# AM335x register map
Vendor: Texas Instruments; Series: Sitara AM335x; File version: 1.1
CPU: Cortex-A8 r0p0, little endian
Registers are 32-bit, read-write, reset 0x0 unless marked. A register's access mark holds for its fields unless they carry their own. Offsets are from the block's base; [hi:lo] are bit positions; 'fields as' and 'values as' point back to an identical list.

## CM_MPU — Clock Module - MPU
Base 0x44E00600
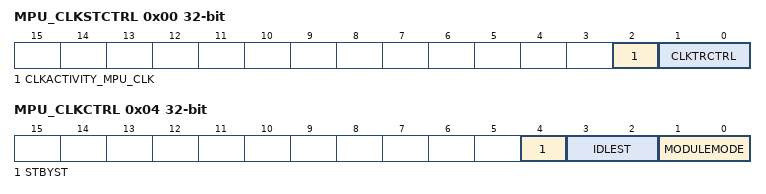
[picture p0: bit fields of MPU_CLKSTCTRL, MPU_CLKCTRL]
0x00 MPU_CLKSTCTRL
  [2] CLKACTIVITY_MPU_CLK — bit: 2 (R)This field indicates the state of the MPU Clock [see e_PRCM_CLK_DOMAIN_ST]
  [1:0] CLKTRCTRL — bit: 0,1 (RW)Clock state transition [see e_PRCM_CLKTRCTRL]
0x04 MPU_CLKCTRL — CM_STBY_CLKCTRL Register
  [4] STBYST — bit: 18 (R)Module standby status.[see e_PRCM_STBYST]
  [3:2] IDLEST — bit: 16,17 (R)Module idle status.[see e_PRCM_IDLEST]
  [1:0] MODULEMODE — bit: 0,1 (RW)Control the way mandatory clocks are managed.[see e_PRCM_MODULEMODE]

## CM_RTC — Clock Module - RTC
Base 0x44E00800
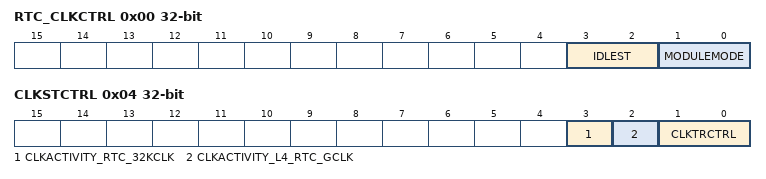
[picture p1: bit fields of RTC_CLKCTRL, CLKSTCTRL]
0x00 RTC_CLKCTRL — CM_CLKCTRL Register
  [3:2] IDLEST — bit: 16,17 (R)Module idle status.[see e_PRCM_IDLEST]
  [1:0] MODULEMODE — bit: 0,1 (RW)Control the way mandatory clocks are managed.[see e_PRCM_MODULEMODE]
0x04 CLKSTCTRL — RTC_CLKSTCTRL Register
  [3] CLKACTIVITY_RTC_32KCLK — bit: 9 (R)This field indicates the state of the 32K RTC clock in the domain [0x0 = Inact; 0x1 = Act]
  [2] CLKACTIVITY_L4_RTC_GCLK — bit: 8 (R)This field indicates the state of the L4 RTC clock in the domain. [0x0 = Inact; 0x1 = Act]
  [1:0] CLKTRCTRL — bit: 0,1 (RW)Clock state transition [see e_PRCM_CLKTRCTRL]

## PRM_CEFUSE — Power Reset Module - CEFUSE
Base 0x44E01200
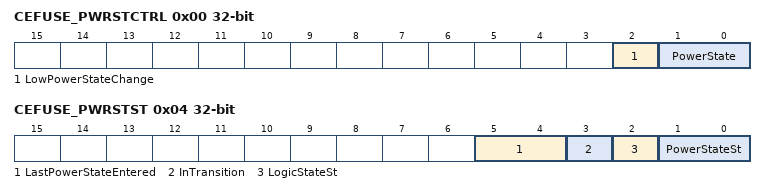
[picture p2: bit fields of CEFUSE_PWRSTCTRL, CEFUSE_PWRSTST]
0x00 CEFUSE_PWRSTCTRL
  [2] LowPowerStateChange — bit: 4 (RW) Power state change request when domain has already performed a sleep transition [0x0 = Do not request; 0x1 = Request a low power state change]
  [1:0] PowerState — bit: 0,1 (RW) Power state control [see e_CEFUSE_PWRSTATE_CTRL]
0x04 CEFUSE_PWRSTST
  [5:4] LastPowerStateEntered — bit: 24,25 (RW)Last low power state entered.Set to 0x3 upon write of the same only. [0x0 = OFF; 0x1 = ON]
  [3] InTransition — bit: 20 (R)Domain transition status [0x0 = No on-going transition; 0x1 = transition is in progress.]
  [2] LogicStateSt — bit: 2 (R)Logic state status [0x0 = logic in domain OFF; 0x1 = logic in domain ON]
  [1:0] PowerStateSt — bit: 0,1 (R)Current Power State Status [see e_CEFUSE_PWRSTST]

## PRM_GFX — Power Reset Module - GFX
Base 0x44E01100
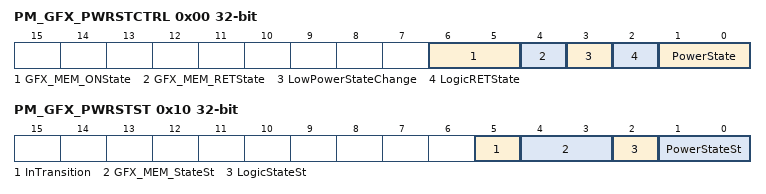
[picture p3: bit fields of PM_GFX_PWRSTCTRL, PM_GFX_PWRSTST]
0x00 PM_GFX_PWRSTCTRL
  [6:5] GFX_MEM_ONState — bit: 17,18 (R) GFX memory state when domain is ON.
  [4] GFX_MEM_RETState — bit: 6 (RW)
  [3] LowPowerStateChange — bit: 4 (RW) Power state change request when domain has already performed a sleep transition [0x0 = Do not request; 0x1 = Request a low power state change]
  [2] LogicRETState — bit: 2 (RW) Logic state when power domain is RETENTION [0x0 = logic_off; 0x1 = logic_ret]
  [1:0] PowerState — bit: 0,1 (RW) Power state control [see e_PWR_STATE_CTRL]
0x04 RM_GFX_RSTCTRL
  [0] GFX_RST — bit: 0 (RW) GFX domain local reset control for (SGX 530) [0x0 = CLEAR; 0x1 = ASSERT]
0x10 PM_GFX_PWRSTST
  [5] InTransition — bit: 20 (R)Domain transition status [0x0 = No on-going transition on power domain; 0x1 = Power domain transition is in progress]
  [4:3] GFX_MEM_StateSt — bit: 4,5 (R)GFX memory state status [see e_GFX_MEMSTST]
  [2] LogicStateSt — bit: 2 (R)Logic state status [0x0 = logic in domain OFF; 0x1 = logic in domain ON]
  [1:0] PowerStateSt — bit: 0,1 (R)Current Power State Status [see e_GFX_PWRSTST]
0x14 RM_GFX_RSTST
  [0] GFX_RST — bit: 0 (RW) GFX Domain Logic Reset [0x0 = RESET_NO; 0x1 = RESET_YES]

## PRM_IRQ — Power Reset Module - IRQ
Base 0x44E00B00
0x00 REVISION
  [7:0] REV — IP revision [7:4] Major revision [3:0] Minor revision Examples: 0x10 for 1.0, 0x21 for 2.1
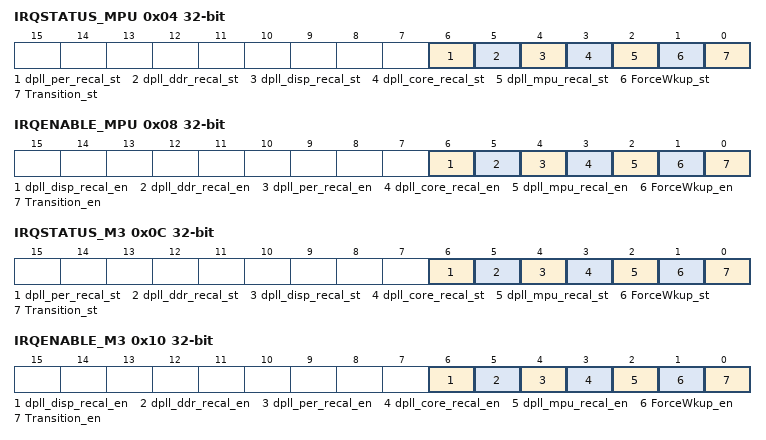
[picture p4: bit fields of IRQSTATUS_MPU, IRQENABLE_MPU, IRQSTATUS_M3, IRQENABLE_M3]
0x04 IRQSTATUS_MPU
  [6] dpll_per_recal_st — bit: 15 (RW)interrupt status for usb dpll recaliberation [0x0 = disable; 0x1 = enable;]
  [5] dpll_ddr_recal_st — bit: 14 (RW)interrupt status for ddr dpll recaliberation [0x0 = disable; 0x1 = enable;]
  [4] dpll_disp_recal_st — bit: 13 (RW)interrupt status for disp dpll recaliberation [0x0 = disable; 0x1 = enable;]
  [3] dpll_core_recal_st — bit: 12 (RW)interrupt status for core dpll recaliberation [0x0 = disable; 0x1 = enable;]
  [2] dpll_mpu_recal_st — bit: 11 (RW)interrupt status for mpu dpll recaliberation [0x0 = disable; 0x1 = enable;]
  [1] ForceWkup_st — bit: 10 (RW)Software supervised wakeup completed event interrupt status [0x0 = IRQ_fal : No interrupt; 0x1 = IRQ_tru : Interrupt is pending;]
  [0] Transition_st — bit: 8 (RW)Software supervised transition completed event interrupt status [0x0 = IRQ_fal : No interrupt; 0x1 = IRQ_tru : Interrupt is pending;]
0x08 IRQENABLE_MPU
  [6] dpll_disp_recal_en — bit: 15 (RW)interrupt status for usb dpll recaliberation [0x0 = disable ; 0x1 = enable ;]
  [5] dpll_ddr_recal_en — bit: 14 (RW)interrupt status for ddr dpll recaliberation [0x0 = disable ; 0x1 = enable ;]
  [4] dpll_per_recal_en — bit: 13 (RW)interrupt status for disp dpll recaliberation [0x0 = disable ; 0x1 = enable ;]
  [3] dpll_core_recal_en — bit: 12 (RW)interrupt status for core dpll recaliberation [0x0 = disable ; 0x1 = enable ;]
  [2] dpll_mpu_recal_en — bit: 11 (RW)Interrupt enable for mpu dpll recaliberation [0x0 = disable ; 0x1 = enable ;]
  [1] ForceWkup_en — bit: 10 (RW)Software supervised Froce Wakeup completed event interruptenable [0x0 = masked; 0x1 = enabled]
  [0] Transition_en — bit: 8 (RW)Software supervised transition completed event interrupt enable (anydomain) [0x0 = masked; 0x1 = enabled]
0x0C IRQSTATUS_M3
  fields as IRQSTATUS_MPU
0x10 IRQENABLE_M3
  fields as IRQENABLE_MPU
